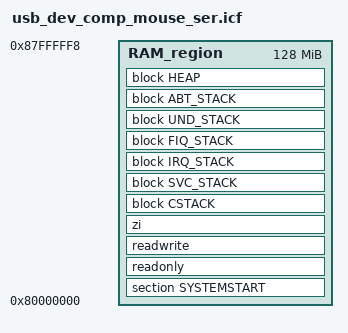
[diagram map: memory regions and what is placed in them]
/*
* Copyright (C) 2010 Texas Instruments Incorporated - http://www.ti.com/ 
*/
/* 
*  Redistribution and use in source and binary forms, with or without 
*  modification, are permitted provided that the following conditions 
*  are met:
*
*    Redistributions of source code must retain the above copyright 
*    notice, this list of conditions and the following disclaimer.
*
*    Redistributions in binary form must reproduce the above copyright
*    notice, this list of conditions and the following disclaimer in the 
*    documentation and/or other materials provided with the   
*    distribution.
*
*    Neither the name of Texas Instruments Incorporated nor the names of
*    its contributors may be used to endorse or promote products derived
*    from this software without specific prior written permission.
*
*  THIS SOFTWARE IS PROVIDED BY THE COPYRIGHT HOLDERS AND CONTRIBUTORS 
*  "AS IS" AND ANY EXPRESS OR IMPLIED WARRANTIES, INCLUDING, BUT NOT 
*  LIMITED TO, THE IMPLIED WARRANTIES OF MERCHANTABILITY AND FITNESS FOR
*  A PARTICULAR PURPOSE ARE DISCLAIMED. IN NO EVENT SHALL THE COPYRIGHT 
*  OWNER OR CONTRIBUTORS BE LIABLE FOR ANY DIRECT, INDIRECT, INCIDENTAL, 
*  SPECIAL, EXEMPLARY, OR CONSEQUENTIAL DAMAGES (INCLUDING, BUT NOT 
*  LIMITED TO, PROCUREMENT OF SUBSTITUTE GOODS OR SERVICES; LOSS OF USE,
*  DATA, OR PROFITS; OR BUSINESS INTERRUPTION) HOWEVER CAUSED AND ON ANY
*  THEORY OF LIABILITY, WHETHER IN CONTRACT, STRICT LIABILITY, OR TORT 
*  (INCLUDING NEGLIGENCE OR OTHERWISE) ARISING IN ANY WAY OUT OF THE USE 
*  OF THIS SOFTWARE, EVEN IF ADVISED OF THE POSSIBILITY OF SUCH DAMAGE.
*
*/

/*###ICF### Section handled by ICF editor, don't touch! ****/
/*-Editor annotation file-*/
/* IcfEditorFile="$TOOLKIT_DIR$\config\ide\IcfEditor\a_v1_0.xml" */
/*-Specials-*/
define symbol __ICFEDIT_intvec_start__ = 0xFFFF0000;

/*-Memory Regions-*/
define symbol __ICFEDIT_region_ROM_start__ = 0x00000000;
define symbol __ICFEDIT_region_ROM_end__   = 0x00000000;
define symbol __ICFEDIT_region_RAM_start__ = 0x80000000;
define symbol __ICFEDIT_region_RAM_end__   = 0x87FFFFF8;
/*-Sizes-*/
define symbol __ICFEDIT_size_cstack__   = 0x5000;
define symbol __ICFEDIT_size_svcstack__ = 0x8;
define symbol __ICFEDIT_size_irqstack__ = 0x1000;
define symbol __ICFEDIT_size_fiqstack__ = 0x8;
define symbol __ICFEDIT_size_undstack__ = 0x8;
define symbol __ICFEDIT_size_abtstack__ = 0x8;
define symbol __ICFEDIT_size_heap__     = 0x0;
/**** End of ICF editor section. ###ICF###*/


define memory mem with size = 4G;
define region RAM_region   = mem:[from __ICFEDIT_region_RAM_start__   to __ICFEDIT_region_RAM_end__];

define block CSTACK    with alignment = 8, size = __ICFEDIT_size_cstack__   { };
define block SVC_STACK with alignment = 8, size = __ICFEDIT_size_svcstack__ { };
define block IRQ_STACK with alignment = 8, size = __ICFEDIT_size_irqstack__ { };
define block FIQ_STACK with alignment = 8, size = __ICFEDIT_size_fiqstack__ { };
define block UND_STACK with alignment = 8, size = __ICFEDIT_size_undstack__ { };
define block ABT_STACK with alignment = 8, size = __ICFEDIT_size_abtstack__ { };
define block HEAP      with alignment = 8, size = __ICFEDIT_size_heap__     { };

do not initialize  { section .noinit };

place in RAM_region   { section SYSTEMSTART };
place in RAM_region   { readonly };
place in RAM_region   { readwrite};
place in RAM_region   { zi };
place in RAM_region   { block CSTACK, block SVC_STACK, block IRQ_STACK, block FIQ_STACK,
                        block UND_STACK, block ABT_STACK, block HEAP };

define exported symbol __intvec_start = __ICFEDIT_intvec_start__;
